# Q32M210 register map
File version: 1.0
Registers are 32-bit, read-write, no defined reset value unless marked. A register's access mark holds for its fields unless they carry their own. Offsets are from the block's base; [hi:lo] are bit positions; {n}, {i} and the like mark numbered series.

## GPIO_and_LCD_Driver_Configuration_and_Control
Base 0x40000500
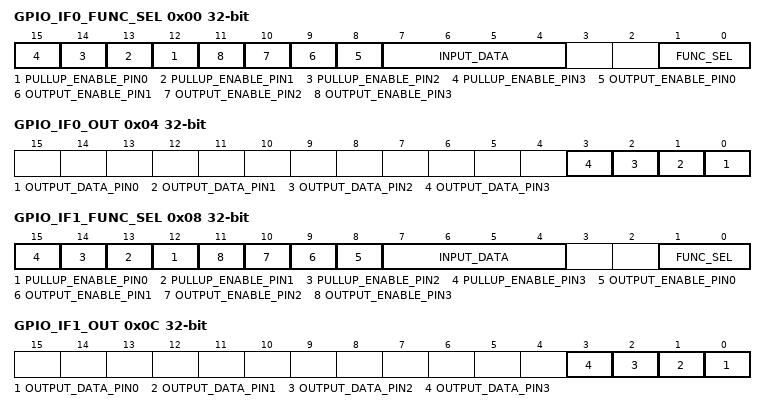
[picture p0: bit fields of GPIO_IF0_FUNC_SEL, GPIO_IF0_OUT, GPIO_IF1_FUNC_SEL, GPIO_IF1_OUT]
0x00 GPIO_IF0_FUNC_SEL — GPIO IF0 Function Select
  [n+12] PULLUP_ENABLE_PIN{n} (n=0..3) — Configure the pull-up resistor for GPIO IF0, pin {n}
    0=GPIO_IF0_PIN{n}_PULLUP_DISABLE (Disable the pull-up resistor for GPIO IF0, pin {n}); 1=GPIO_IF0_PIN{n}_PULLUP_ENABLE (Enable the pull-up resistor for GPIO IF0, pin {n})
  [n+8] OUTPUT_ENABLE_PIN{n} (n=0..3) — Enable output on GPIO IF0, pin {n}
    0=GPIO_IF0_PIN{n}_OUTPUT_DISABLE (Disable output on GPIO IF0, pin {n}); 1=GPIO_IF0_PIN{n}_OUTPUT_ENABLE (Enable output on GPIO IF0, pin {n})
  [7:4] INPUT_DATA — Input data from GPIO IF0
  [1:0] FUNC_SEL — Select the multiplexed function for the GPIO IF0 pins
    0=GPIO_IF0_SELECT_SPI0 (Enables the SPI0 multiplexed function of GPIO IF0); 1=GPIO_IF0_SELECT_GPIO (Enables the GPIO multiplexed function of GPIO IF0); 2=GPIO_IF0_SELECT_USR_CLK (Enables the user clock multiplexed function of GPIO IF0 (IF0, Pin 0 set to ground))
0x04 GPIO_IF0_OUT — GPIO IF0 Output
  [n] OUTPUT_DATA_PIN{n} (n=0..3) — Output data for GPIO IF0, pin {n}
0x08 GPIO_IF1_FUNC_SEL — GPIO IF1 Function Select
  [n+12] PULLUP_ENABLE_PIN{n} (n=0..3) — Configure the pull-up resistor for GPIO IF1, pin {n}
    0=GPIO_IF1_PIN{n}_PULLUP_DISABLE (Disable the pull-up resistor for GPIO IF1, pin {n}); 1=GPIO_IF1_PIN{n}_PULLUP_ENABLE (Enable the pull-up resistor for GPIO IF1, pin {n})
  [n+8] OUTPUT_ENABLE_PIN{n} (n=0..3) — Enable output on GPIO IF1, pin {n}
    0=GPIO_IF1_PIN{n}_OUTPUT_DISABLE (Disable output on GPIO IF1, pin {n}); 1=GPIO_IF1_PIN{n}_OUTPUT_ENABLE (Enable output on GPIO IF1, pin {n})
  [7:4] INPUT_DATA — Input data from GPIO IF1
  [1:0] FUNC_SEL — Select the multiplexed function for the GPIO IF1 pins
    0=GPIO_IF1_SELECT_SPI1 (Enables the SPI0 multiplexed function of GPIO IF1); 1=GPIO_IF1_SELECT_GPIO (Enables the GPIO multiplexed function of GPIO IF1); 2=GPIO_IF1_SELECT_PCM (Enables the PCM multiplexed function of GPIO IF1)
0x0C GPIO_IF1_OUT — GPIO IF1 Output
  [n] OUTPUT_DATA_PIN{n} (n=0..3) — Output data for GPIO IF1, pin {n}
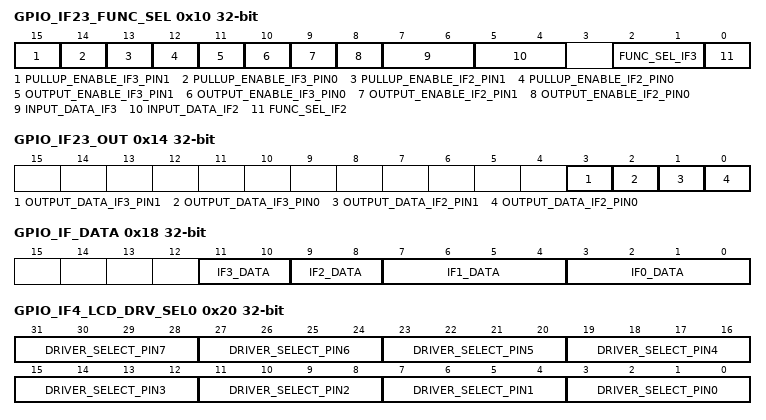
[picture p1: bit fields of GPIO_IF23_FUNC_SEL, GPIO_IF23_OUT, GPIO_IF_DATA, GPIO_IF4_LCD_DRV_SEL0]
0x10 GPIO_IF23_FUNC_SEL — GPIO IF2/IF3 Function Select
  [15] PULLUP_ENABLE_IF3_PIN1 — Configure the pull-up resistor for GPIO IF3, pin 1
    0=GPIO_IF3_PIN1_PULLUP_DISABLE (Disable the pull-up resistor for GPIO IF3, pin 1); 1=GPIO_IF3_PIN1_PULLUP_ENABLE (Enable the pull-up resistor for GPIO IF3, pin 1)
  [14] PULLUP_ENABLE_IF3_PIN0 — Configure the pull-up resistor for GPIO IF3, pin 0
    0=GPIO_IF3_PIN0_PULLUP_DISABLE (Disable the pull-up resistor for GPIO IF3, pin 0); 1=GPIO_IF3_PIN0_PULLUP_ENABLE (Enable the pull-up resistor for GPIO IF3, pin 0)
  [13] PULLUP_ENABLE_IF2_PIN1 — Configure the pull-up resistor for GPIO IF2, pin 1
    0=GPIO_IF2_PIN1_PULLUP_DISABLE (Disable the pull-up resistor for GPIO IF2, pin 1); 1=GPIO_IF2_PIN1_PULLUP_ENABLE (Enable the pull-up resistor for GPIO IF2, pin 1)
  [12] PULLUP_ENABLE_IF2_PIN0 — Configure the pull-up resistor for GPIO IF2, pin 0
    0=GPIO_IF2_PIN0_PULLUP_DISABLE (Disable the pull-up resistor for GPIO IF2, pin 0); 1=GPIO_IF2_PIN0_PULLUP_ENABLE (Enable the pull-up resistor for GPIO IF2, pin 0)
  [11] OUTPUT_ENABLE_IF3_PIN1 — Enable output on GPIO IF3, pin 1
    0=GPIO_IF3_PIN1_OUTPUT_DISABLE (Disable output on GPIO IF3, pin 1); 1=GPIO_IF3_PIN1_OUTPUT_ENABLE (Enable output on GPIO IF3, pin 1)
  [10] OUTPUT_ENABLE_IF3_PIN0 — Enable output on GPIO IF3, pin 0
    0=GPIO_IF3_PIN0_OUTPUT_DISABLE (Disable output on GPIO IF3, pin 0); 1=GPIO_IF3_PIN0_OUTPUT_ENABLE (Enable output on GPIO IF3, pin 0)
  [9] OUTPUT_ENABLE_IF2_PIN1 — Enable output on GPIO IF2, pin 1
    0=GPIO_IF2_PIN1_OUTPUT_DISABLE (Disable output on GPIO IF2, pin 1); 1=GPIO_IF2_PIN1_OUTPUT_ENABLE (Enable output on GPIO IF2, pin 1)
  [8] OUTPUT_ENABLE_IF2_PIN0 — Enable output on GPIO IF2, pin 0
    0=GPIO_IF2_PIN0_OUTPUT_DISABLE (Disable output on GPIO IF2, pin 0); 1=GPIO_IF2_PIN0_OUTPUT_ENABLE (Enable output on GPIO IF2, pin 0)
  [7:6] INPUT_DATA_IF3 — Input data from GPIO IF3
  [5:4] INPUT_DATA_IF2 — Input data from GPIO IF2
  [2:1] FUNC_SEL_IF3 — Select the multiplexed function for the GPIO IF3 pins
    0=GPIO_IF3_SELECT_UART1 (Enables the UART1 multiplexed function of GPIO IF3); 1=GPIO_IF3_SELECT_GPIO (Enables the GPIO multiplexed function of GPIO IF3); 2=GPIO_IF3_SELECT_SQI (Enables the SQI multiplexed function of GPIO IF3)
  [0] FUNC_SEL_IF2 — Select the multiplexed function for the GPIO IF2 pins
    0=GPIO_IF2_SELECT_UART0 (Enables the UART0 multiplexed function of GPIO IF2); 1=GPIO_IF2_SELECT_GPIO (Enables the GPIO multiplexed function of GPIO IF2)
0x14 GPIO_IF23_OUT — GPIO IF2/IF3 Output
  [3] OUTPUT_DATA_IF3_PIN1 — Output data from GPIO IF3, pin 1
  [2] OUTPUT_DATA_IF3_PIN0 — Output data from GPIO IF3, pin 0
  [1] OUTPUT_DATA_IF2_PIN1 — Output data from GPIO IF2, pin 1
  [0] OUTPUT_DATA_IF2_PIN0 — Output data from GPIO IF2, pin 0
0x18 GPIO_IF_DATA — GPIO IF0 to IF3 Collected Input and Output
  [11:10] IF3_DATA — Inputs (read) and outputs (write) for IF3
  [9:8] IF2_DATA — Inputs (read) and outputs (write) for IF2
  [7:4] IF1_DATA — Inputs (read) and outputs (write) for IF1
  [3:0] IF0_DATA — Inputs (read) and outputs (write) for IF0
0x1C GPIO_IF4_LCD_FUNC_SEL — GPIO IF4, LCD Driver Function Select
  [31:0] FUNC_SEL — Select the multiplexed function for the GPIO IF4 pins (set to 0 for GPIO, 1 for LCD driver)
    0=GPIO_IF4_ALL_GPIO (Enables the GPIO multiplexed function of GPIO IF4); 0xFFFFFFFF=GPIO_IF4_ALL_LCD (Enables the LCD driver multiplexed function of GPIO IF4)
0x20 GPIO_IF4_LCD_DRV_SEL0 — GPIO IF4, LCD Driver Select 0
  [4n+3:4n] DRIVER_SELECT_PIN{n} (n=0..7) — Select the LCD driver waveform for segment {n} (GPIO IF4, pin {n+4})
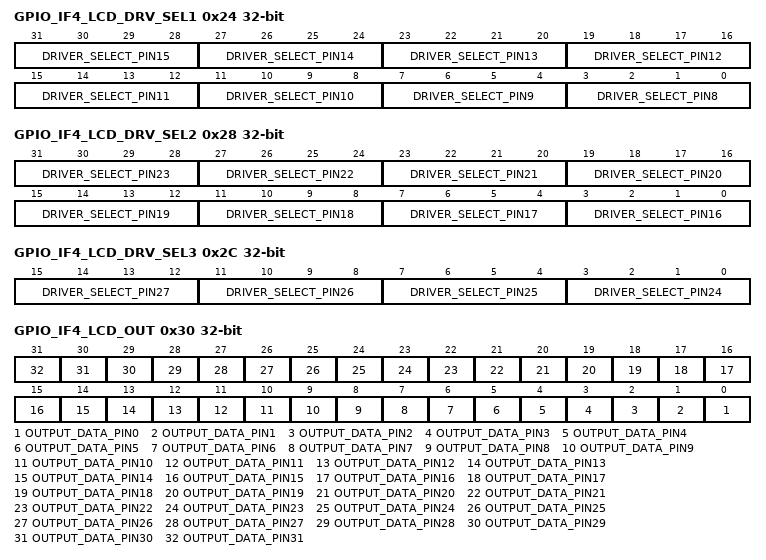
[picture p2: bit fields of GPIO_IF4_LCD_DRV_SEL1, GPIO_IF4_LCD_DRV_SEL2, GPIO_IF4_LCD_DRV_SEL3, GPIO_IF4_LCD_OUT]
0x24 GPIO_IF4_LCD_DRV_SEL1 — GPIO IF4, LCD Driver Select 1
  [4n-29:4n-32] DRIVER_SELECT_PIN{n} (n=8..15) — Select the LCD driver waveform for segment {n} (GPIO IF4, pin {n+4})
0x28 GPIO_IF4_LCD_DRV_SEL2 — GPIO IF4, LCD Driver Select 2
  [4n-61:4n-64] DRIVER_SELECT_PIN{n} (n=16..23) — Select the LCD driver waveform for segment {n} (GPIO IF4, pin {n+4})
0x2C GPIO_IF4_LCD_DRV_SEL3 — GPIO IF4, LCD Driver Select 3
  [4n-93:4n-96] DRIVER_SELECT_PIN{n} (n=24..27) — Select the LCD driver waveform for segment {n} (GPIO IF4, pin {n+4})
0x30 GPIO_IF4_LCD_OUT — GPIO IF4, LCD Driver Output
  [n] OUTPUT_DATA_PIN{n} (n=0..31) — Output data for GPIO IF4, pin {n}
0x34 GPIO_IF4_LCD_OE — GPIO IF4, LCD Driver Output Enable
  [31:0] OUTPUT_ENABLE — Output enable for GPIO IF4 (set to 0 to disable output, 1 to enable output)
    0=GPIO_IF4_OUTPUT_DISABLE_ALL (Disable output on all GPIO IF4 pins); 0xFFFFFFFF=GPIO_IF4_OUTPUT_ENABLE_ALL (Enable output on all GPIO IF4 pins)
0x38 GPIO_IF4_LCD_IN — GPIO IF4, LCD Driver Input
  [31:0] INPUT_DATA — Input data from GPIO IF4
0x3C GPIO_IF4_LCD_PULLDOWN — GPIO IF4, LCD Driver Pull-down Configuration
  [31:0] ENABLE — Configure pull-down resistors for GPIO IF4 (set to 0 to disable the pull-down resistor, 1 to enable the pull-down resistor)
    0=GPIO_IF4_PULLDOWN_DISABLE_ALL (Disable pull-down resistors for all GPIO IF4 pins); 0xFFFFFFFF=GPIO_IF4_PULLDOWN_ENABLE_ALL (Enable pull-down resistors for all GPIO IF4 pins)
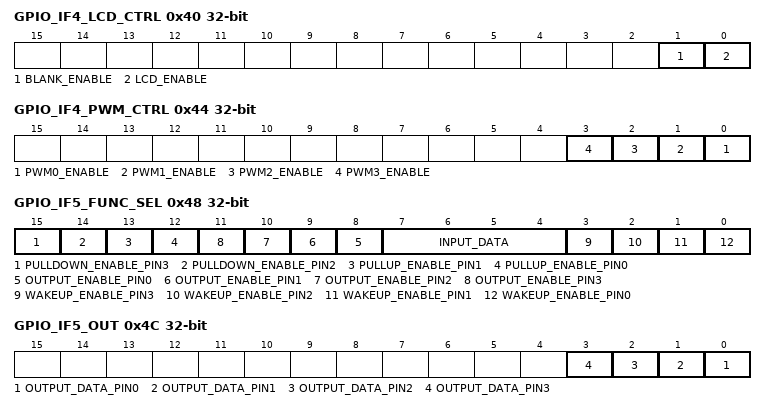
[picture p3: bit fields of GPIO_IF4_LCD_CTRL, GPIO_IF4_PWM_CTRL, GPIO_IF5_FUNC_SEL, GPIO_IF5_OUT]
0x40 GPIO_IF4_LCD_CTRL — GPIO LCD Driver Control
  [1] BLANK_ENABLE — Select whether the LCD segment output is blanked
    0=LCD_BLANK_DISABLE (LCD segment output is defined by the driver selection for that segment); 1=LCD_BLANK_ENABLE (All LCD segments are blanked)
  [0] LCD_ENABLE — Enable the LCD driver
    0=LCD_DISABLE (LCD segment and backplane signals are pulled to ground); 1=LCD_ENABLE (LCD segment signals controlled by the LCD blank setting and segment configuration)
0x44 GPIO_IF4_PWM_CTRL — GPIO Pulse-Width Modulator Control
  [n] PWM{n}_ENABLE (n=0..3) — Enable PWM{n} output. Overrides the GPIO {n+32} (GPIO IF4 pin {n+24} and LCD driver segment {n+24}) configuration.
    0=PWM{n}_DISABLE (Use GPIO IF4, LCD driver function configuration for GPIO {n+32}); 1=PWM{n}_ENABLE (Enable PWM{n} output on GPIO {n+32})
0x48 GPIO_IF5_FUNC_SEL — GPIO IF5, Wakeup Function Select
  [15] PULLDOWN_ENABLE_PIN3 — Configure the pull-down resistor for GPIO IF5, pin 3
    0=GPIO_IF5_PIN3_PULLDOWN_DISABLE (Disable the pull-down resistor for GPIO IF5, pin 3); 1=GPIO_IF5_PIN3_PULLDOWN_ENABLE (Enable the pull-down resistor for GPIO IF5, pin 3)
  [14] PULLDOWN_ENABLE_PIN2 — Configure the pull-down resistor for GPIO IF5, pin 2
    0=GPIO_IF5_PIN2_PULLDOWN_DISABLE (Disable the pull-down resistor for GPIO IF5, pin 2); 1=GPIO_IF5_PIN2_PULLDOWN_ENABLE (Enable the pull-down resistor for GPIO IF5, pin 2)
  [13] PULLUP_ENABLE_PIN1 — Configure the pull-up resistor for GPIO IF5, pin 1
    0=GPIO_IF5_PIN1_PULLUP_DISABLE (Disable the pull-up resistor for GPIO IF5, pin 1); 1=GPIO_IF5_PIN1_PULLUP_ENABLE (Enable the pull-up resistor for GPIO IF5, pin 1)
  [12] PULLUP_ENABLE_PIN0 — Configure the pull-up resistor for GPIO IF5, pin 0
    0=GPIO_IF5_PIN0_PULLUP_DISABLE (Disable the pull-up resistor for GPIO IF5, pin 0); 1=GPIO_IF5_PIN0_PULLUP_ENABLE (Enable the pull-up resistor for GPIO IF5, pin 0)
  [n+8] OUTPUT_ENABLE_PIN{n} (n=0..3) — Enable output on GPIO IF5, pin {n}
    0=GPIO_IF5_PIN{n}_OUTPUT_DISABLE (Disable output on GPIO IF5, pin {n}); 1=GPIO_IF5_PIN{n}_OUTPUT_ENABLE (Enable output on GPIO IF5, pin {n})
  [7:4] INPUT_DATA — Input data from GPIO IF5
  [3] WAKEUP_ENABLE_PIN3 — Enable wakeup for high-to-low transition GPIO IF5, pin 3
    0=GPIO_IF5_PIN3_WAKEUP_DISABLE (Disable wakeup controller for GPIO IF5, pin 3); 1=GPIO_IF5_PIN3_WAKEUP_ENABLE (Enable wakeup controller for GPIO IF5, pin 3)
  [2] WAKEUP_ENABLE_PIN2 — Enable wakeup for high-to-low transition GPIO IF5, pin 2
    0=GPIO_IF5_PIN2_WAKEUP_DISABLE (Disable wakeup controller for GPIO IF5, pin 2); 1=GPIO_IF5_PIN2_WAKEUP_ENABLE (Enable wakeup controller for GPIO IF5, pin 2)
  [1] WAKEUP_ENABLE_PIN1 — Enable wakeup for low-to-high transition GPIO IF5, pin 1
    0=GPIO_IF5_PIN1_WAKEUP_DISABLE (Disable wakeup controller for GPIO IF5, pin 1); 1=GPIO_IF5_PIN1_WAKEUP_ENABLE (Enable wakeup controller for GPIO IF5, pin 1)
  [0] WAKEUP_ENABLE_PIN0 — Enable wakeup for low-to-high transition GPIO IF5, pin 0
    0=GPIO_IF5_PIN0_WAKEUP_DISABLE (Disable wakeup controller for GPIO IF5, pin 0); 1=GPIO_IF5_PIN0_WAKEUP_ENABLE (Enable wakeup controller for GPIO IF5, pin 0)
0x4C GPIO_IF5_OUT — GPIO IF5, Wakeup Output
  [n] OUTPUT_DATA_PIN{n} (n=0..3) — Output data for GPIO IF5, pin {n}
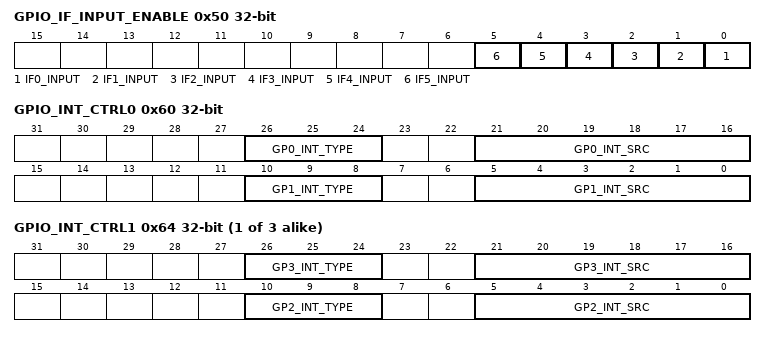
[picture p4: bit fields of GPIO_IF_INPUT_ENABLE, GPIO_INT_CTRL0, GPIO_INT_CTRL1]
0x50 GPIO_IF_INPUT_ENABLE — GPIO Interface Input Enable
  [n] IF{n}_INPUT (n=0..5) — Enable input sampling on GPIO IF{n}
    0=GPIO_IF{n}_IN_DISABLE (Disable input signals on GPIO IF{n}); 1=GPIO_IF{n}_IN_ENABLE (Enable input signals on GPIO IF{n})
0x60 GPIO_INT_CTRL0 — GPIO Interrupt Control 0
  [26:24] GP0_INT_TYPE — Configure general-purpose GPIO interrupt 0
    0=GPIO_GP0_INT_DISABLE (The GPIO GP0 interrupt is disabled); 2=GPIO_GP0_INT_LOW_TRIGGER (GPIO GP0 interrupt is triggered on a low-level signal); 3=GPIO_GP0_INT_HIGH_TRIGGER (GPIO GP0 interrupt is triggered on a high-level signal); 4=GPIO_GP0_INT_EDGE_TRIGGER (GPIO GP0 interrupt is triggered on a positive or negative edge); 6=GPIO_GP0_INT_NEG_EDGE_TRIGGER (GPIO GP0 interrupt is triggered on a negative edge); 7=GPIO_GP0_INT_POS_EDGE_TRIGGER (GPIO GP0 interrupt is triggered on a positive edge)
  [21:16] GP0_INT_SRC — Select the source for general-purpose GPIO interrupt 0
  [10:8] GP1_INT_TYPE — Configure general-purpose GPIO interrupt 1
    0=GPIO_GP1_INT_DISABLE (The GPIO GP1 interrupt is disabled); 2=GPIO_GP1_INT_LOW_TRIGGER (GPIO GP1 interrupt is triggered on a low-level signal); 3=GPIO_GP1_INT_HIGH_TRIGGER (GPIO GP1 interrupt is triggered on a high-level signal); 4=GPIO_GP1_INT_EDGE_TRIGGER (GPIO GP1 interrupt is triggered on a positive or negative edge); 6=GPIO_GP1_INT_NEG_EDGE_TRIGGER (GPIO GP1 interrupt is triggered on a negative edge); 7=GPIO_GP1_INT_POS_EDGE_TRIGGER (GPIO GP1 interrupt is triggered on a positive edge)
  [5:0] GP1_INT_SRC — Select the source for general-purpose GPIO interrupt 1
{0x60+4i} GPIO_INT_CTRL{i} (i=1..3) — GPIO Interrupt Control {i}
  [26:24] GP{2i+1}_INT_TYPE — Configure general-purpose GPIO interrupt {2i+1}
    0=GPIO_GP{2i+1}_INT_DISABLE (The GPIO GP{2i+1} interrupt is disabled); 2=GPIO_GP{2i+1}_INT_LOW_TRIGGER (GPIO GP{2i+1} interrupt is triggered on a low-level signal); 3=GPIO_GP{2i+1}_INT_HIGH_TRIGGER (GPIO GP{2i+1} interrupt is triggered on a high-level signal); 4=GPIO_GP{2i+1}_INT_EDGE_TRIGGER (GPIO GP{2i+1} interrupt is triggered on a positive or negative edge); 6=GPIO_GP{2i+1}_INT_NEG_EDGE_TRIGGER (GPIO GP{2i+1} interrupt is triggered on a negative edge); 7=GPIO_GP{2i+1}_INT_POS_EDGE_TRIGGER (GPIO GP{2i+1} interrupt is triggered on a positive edge)
  [21:16] GP{2i+1}_INT_SRC — Select the source for general-purpose GPIO interrupt {2i+1}
  [10:8] GP{2i}_INT_TYPE — Configure general-purpose GPIO interrupt {2i}
    0=GPIO_GP{2i}_INT_DISABLE (The GPIO GP{2i} interrupt is disabled); 2=GPIO_GP{2i}_INT_LOW_TRIGGER (GPIO GP{2i} interrupt is triggered on a low-level signal); 3=GPIO_GP{2i}_INT_HIGH_TRIGGER (GPIO GP{2i} interrupt is triggered on a high-level signal); 4=GPIO_GP{2i}_INT_EDGE_TRIGGER (GPIO GP{2i} interrupt is triggered on a positive or negative edge); 6=GPIO_GP{2i}_INT_NEG_EDGE_TRIGGER (GPIO GP{2i} interrupt is triggered on a negative edge); 7=GPIO_GP{2i}_INT_POS_EDGE_TRIGGER (GPIO GP{2i} interrupt is triggered on a positive edge)
  [5:0] GP{2i}_INT_SRC — Select the source for general-purpose GPIO interrupt {2i}
